# LPC55S66_cm33_core1 register map
Vendor: nxp.com; File version: 1.0
CPU: CM33 r2p0, little endian, no MPU, no FPU, VTOR, 3 interrupt priority bits
Registers are 32-bit, read-write, reset 0x0 unless marked. A register's access mark holds for its fields unless they carry their own. Offsets are from the block's base; [hi:lo] are bit positions; {n}, {i} and the like mark numbered series; 'fields as' and 'values as' point back to an identical list.

## ANACTRL — ANALOGCTRL
Base 0x40013000
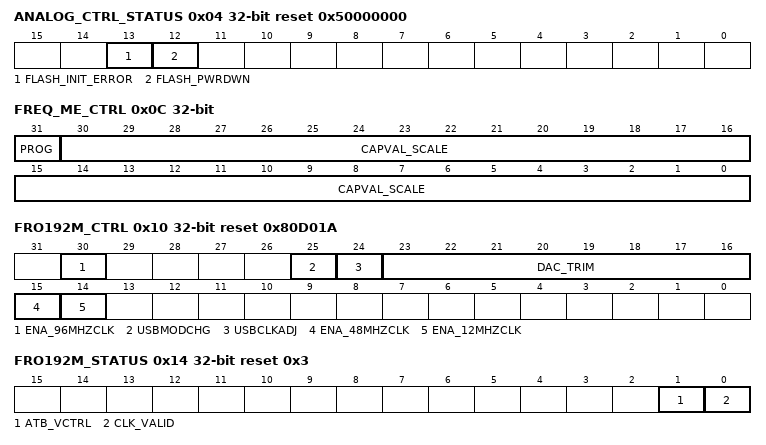
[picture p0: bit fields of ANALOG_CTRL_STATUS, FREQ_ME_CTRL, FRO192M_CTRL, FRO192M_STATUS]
0x04 ANALOG_CTRL_STATUS ro reset 0x50000000 — Analog Macroblock Identity registers, Flash Status registers
  [13] FLASH_INIT_ERROR — Flash initialization error status.
    0=NOERROR; 1=ERROR (At least one error occured during flash initialization..)
  [12] FLASH_PWRDWN — Flash Power Down status.
    0=PWRUP (Flash is not in power down mode.); 1=PWRDWN (Flash is in power down mode.)
0x0C FREQ_ME_CTRL — Frequency Measure function control register
  [31] PROG — Set this bit to one to initiate a frequency measurement cycle. Hardware clears this bit when the measurement cycle has completed and there is valid capture data in the CAPVAL field (bits 30:0).
  [30:0] CAPVAL_SCALE — Frequency measure result /Frequency measur scale
0x10 FRO192M_CTRL reset 0x80D01A — 192MHz Free Running OScillator (FRO) Control register
  [30] ENA_96MHZCLK — 96 MHz clock control.
    0=DISABLE (96 MHz clock is disabled.); 1=ENABLE (96 MHz clock is enabled.)
  [25] USBMODCHG ro — If it reads as 1 when reading the DAC_TRIM field and USBCLKADJ=1, it should be re-read until it is 0.
  [24] USBCLKADJ — If this bit is set and the USB peripheral is enabled into full speed device mode, the USB block will provide FRO clock adjustments to lock it to the host clock using the SOF packets.
  [23:16] DAC_TRIM — Frequency trim.
  [15] ENA_48MHZCLK — 48 MHz clock control.
    1=ENABLE (48 MHz clock is enabled.)
  [14] ENA_12MHZCLK — 12 MHz clock control.
    0=DISABLE (12 MHz clock is disabled.); 1=ENABLE (12 MHz clock is enabled.)
0x14 FRO192M_STATUS reset 0x3 — 192MHz Free Running OScillator (FRO) Status register
  [1] ATB_VCTRL ro — CCO threshold voltage detector output (signal vcco_ok). Once the CCO voltage crosses the threshold voltage of a SLVT transistor, this output signal will go high. It is also possible to observe the clk_valid signal.
  [0] CLK_VALID ro — Output clock valid signal. Indicates that CCO clock has settled.
    0=NOCLKOUT (No output clock present (None of 12 MHz, 48 MHz or 96 MHz clock is available).); 1=CLKOUT (Clock is present (12 MHz, 48 MHz or 96 MHz can be output if they are enable respectively by FRO192M_CTRL.ENA_12MHZCLK/ENA_48MHZCLK/ENA_96MHZCLK).)
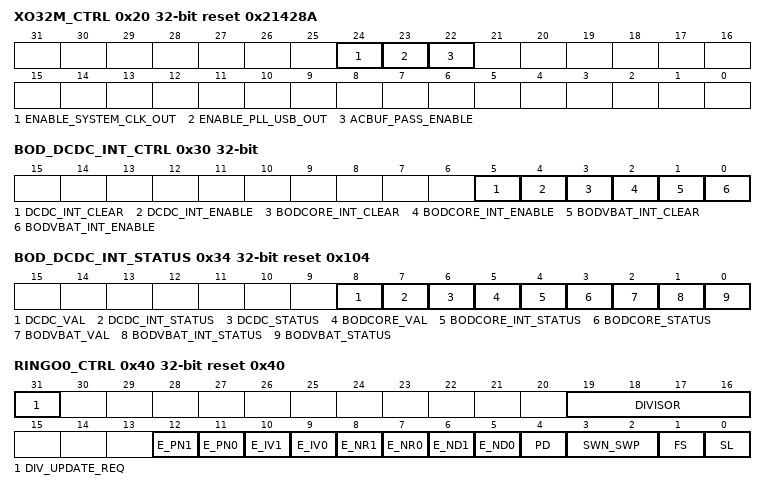
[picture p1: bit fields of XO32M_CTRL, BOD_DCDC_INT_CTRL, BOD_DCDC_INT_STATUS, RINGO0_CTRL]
0x20 XO32M_CTRL reset 0x21428A — High speed Crystal Oscillator Control register
  [24] ENABLE_SYSTEM_CLK_OUT — Enable XO 32 MHz output to CPU system.
    0=DISABLE (High speed Crystal oscillator output to CPU system is disabled.); 1=ENABLE (High speed Crystal oscillator output to CPU system is enabled.)
  [23] ENABLE_PLL_USB_OUT — Enable High speed Crystal oscillator output to USB HS PLL.
    0=DISABLE (High speed Crystal oscillator output to USB HS PLL is disabled.); 1=ENABLE (High speed Crystal oscillator output to USB HS PLL is enabled.)
  [22] ACBUF_PASS_ENABLE — Bypass enable of XO AC buffer enable in pll and top level.
    0=DISABLE (XO AC buffer bypass is disabled.); 1=ENABLE (XO AC buffer bypass is enabled.)
0x24 XO32M_STATUS ro — High speed Crystal Oscillator Status register
  [0] XO_READY — Indicates XO out frequency statibilty.
    0=NOT_STABLE (XO output frequency is not yet stable.); 1=STABLE (XO output frequency is stable.)
0x30 BOD_DCDC_INT_CTRL — Brown Out Detectors (BoDs) & DCDC interrupts generation control register
  [5] DCDC_INT_CLEAR — DCDC interrupt clear.1: Clear the interrupt. Self-cleared bit.
  [4] DCDC_INT_ENABLE — DCDC interrupt control.
    0=DISABLE (DCDC interrupt is disabled.); 1=ENABLE (DCDC interrupt is enabled.)
  [3] BODCORE_INT_CLEAR — BOD CORE interrupt clear.1: Clear the interrupt. Self-cleared bit.
  [2] BODCORE_INT_ENABLE — BOD CORE interrupt control.
    0=DISABLE (BOD CORE interrupt is disabled.); 1=ENABLE (BOD CORE interrupt is enabled.)
  [1] BODVBAT_INT_CLEAR — BOD VBAT interrupt clear.1: Clear the interrupt. Self-cleared bit.
  [0] BODVBAT_INT_ENABLE — BOD VBAT interrupt control.
    0=DISABLE (BOD VBAT interrupt is disabled.); 1=ENABLE (BOD VBAT interrupt is enabled.)
0x34 BOD_DCDC_INT_STATUS ro reset 0x104 — BoDs & DCDC interrupts status register
  [8] DCDC_VAL — Current value of DCDC power status output.
    0=NOT_OK (DCDC output Voltage is below the targeted regulation level.); 1=OK (DCDC output Voltage is above the targeted regulation level.)
  [7] DCDC_INT_STATUS — DCDC Interrupt status after Interrupt Enable.
    0=NOT_PENDING (No interrupt pending..); 1=PENDING (Interrupt pending..)
  [6] DCDC_STATUS — DCDC Interrupt status before Interrupt Enable.
    values as DCDC_INT_STATUS
  [5] BODCORE_VAL — Current value of BOD CORE power status output.
    0=NOT_OK (CORE voltage level is below the threshold.); 1=OK (CORE voltage level is above the threshold.)
  [4] BODCORE_INT_STATUS — BOD CORE Interrupt status after Interrupt Enable.
    values as DCDC_INT_STATUS
  [3] BODCORE_STATUS — BOD CORE Interrupt status before Interrupt Enable.
    values as DCDC_INT_STATUS
  [2] BODVBAT_VAL — Current value of BOD VBAT power status output.
    0=NOT_OK (VBAT voltage level is below the threshold.); 1=OK (VBAT voltage level is above the threshold.)
  [1] BODVBAT_INT_STATUS — BOD VBAT Interrupt status after Interrupt Enable.
    values as DCDC_INT_STATUS
  [0] BODVBAT_STATUS — BOD VBAT Interrupt status before Interrupt Enable.
    values as DCDC_INT_STATUS
0x40 RINGO0_CTRL reset 0x40 — First Ring Oscillator module control register.
  [31] DIV_UPDATE_REQ ro — Ringo clock out Divider status flag. Set when a change is made to the divider value, cleared when the change is complete.
  [19:16] DIVISOR — Ringo out Clock divider value. Frequency Output = Frequency input / (DIViSOR+1). (minimum = Frequency input / 16)
  [12] E_PN1 — Second PN (P-Transistor and N-Transistor processing) monitor control.
    0=DISABLE (Second PN-based ringo is disabled.); 1=ENABLE (Second PN-based ringo is enabled.)
  [11] E_PN0 — First PN (P-Transistor and N-Transistor processing) monitor control.
    0=DISABLE (First PN-based ringo is disabled.); 1=ENABLE (First PN-based ringo is enabled.)
  [10] E_IV1 — Second Inverter-based ringo control.
    0=DISABLE (Second INV-based ringo is disabled.); 1=ENABLE (Second INV-based ringo is enabled.)
  [9] E_IV0 — First Inverter-based ringo control.
    0=DISABLE (First INV-based ringo is disabled.); 1=ENABLE (First INV-based ringo is enabled.)
  [8] E_NR1 — Second NOR2-based ringo control.
    0=DISABLE (Second NORD2-based ringo is disabled.); 1=ENABLE (Second NORD2-based ringo is enabled.)
  [7] E_NR0 — First NOR2-based ringo control.
    0=DISABLE (First NOR2-based ringo is disabled.); 1=ENABLE (First NOR2-based ringo is enabled.)
  [6] E_ND1 — Second NAND2-based ringo control.
    0=DISABLE (Second NAND2-based ringo is disabled.); 1=ENABLE (Second NAND2-based ringo is enabled.)
  [5] E_ND0 — First NAND2-based ringo control.
    0=DISABLE (First NAND2-based ringo is disabled.); 1=ENABLE (First NAND2-based ringo is enabled.)
  [4] PD — Ringo module Power control.
    0=POWERED_ON (The Ringo module is enabled.); 1=POWERED_DOWN (The Ringo module is disabled.)
  [3:2] SWN_SWP — PN-Ringos (P-Transistor and N-Transistor processing) control.
    0=NORMAL (Normal mode.); 1=P_MONITOR (P-Monitor mode. Measure with weak P transistor.); 2=N_MONITOR (P-Monitor mode. Measure with weak N transistor.); 3=FORBIDDEN (Don't use.)
  [1] FS — Ringo frequency output divider.
    0=FAST (High frequency output (frequency lower than 100 MHz).); 1=SLOW (Low frequency output (frequency lower than 10 MHz).)
  [0] SL — Select short or long ringo (for all ringos types).
    0=SHORT (Select short ringo (few elements).); 1=LONG (Select long ringo (many elements).)
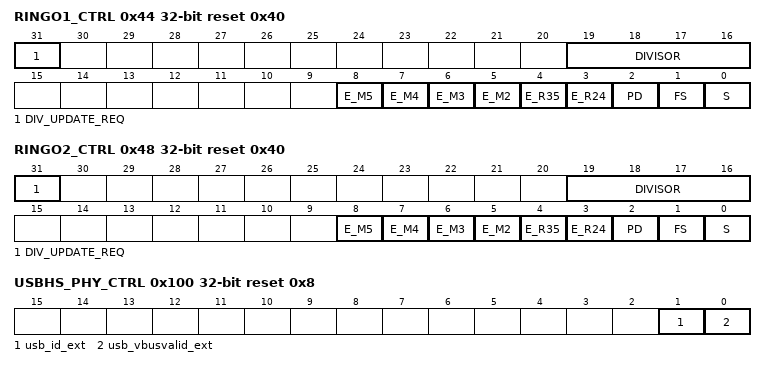
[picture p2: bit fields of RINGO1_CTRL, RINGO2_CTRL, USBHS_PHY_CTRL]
0x44 RINGO1_CTRL reset 0x40 — Second Ring Oscillator module control register.
  [31] DIV_UPDATE_REQ ro — Ringo clock out Divider status flag. Set when a change is made to the divider value, cleared when the change is complete.
  [19:16] DIVISOR — Ringo out Clock divider value. Frequency Output = Frequency input / (DIViSOR+1). (minimum = Frequency input / 16)
  [n+3] E_M{n} (n=2..5) — Metal {n} (M{n}) monitor control.
    0=DISABLE (Ringo is disabled.); 1=ENABLE (Ringo is enabled.)
  [4] E_R35
    0=DISABLE (Ringo is disabled.); 1=ENABLE (Ringo is enabled.)
  [3] E_R24
    0=DISABLE (Ringo is disabled.); 1=ENABLE (Ringo is enabled.)
  [2] PD — Ringo module Power control.
    values as RINGO0_CTRL.PD
  [1] FS — Ringo frequency output divider.
    values as RINGO0_CTRL.FS
  [0] S — Select short or long ringo (for all ringos types).
    values as RINGO0_CTRL.SL
0x48 RINGO2_CTRL reset 0x40 — Third Ring Oscillator module control register.
  fields as RINGO1_CTRL
0x100 USBHS_PHY_CTRL reset 0x8 — USB High Speed Phy Control
  [1] usb_id_ext — Override value for ID if using external detectors.
  [0] usb_vbusvalid_ext — Override value for Vbus if using external detectors.
